# M55M1 register map
File version: 1.0
Registers are 32-bit, read-write, reset 0x0 unless marked. A register's access mark holds for its fields unless they carry their own. Offsets are from the block's base; [hi:lo] are bit positions; 'fields as' and 'values as' point back to an identical list.

## TTMR01 — TTMR Register Map
Base 0x40441000
Same registers: TTMR01_NS 0x50441000
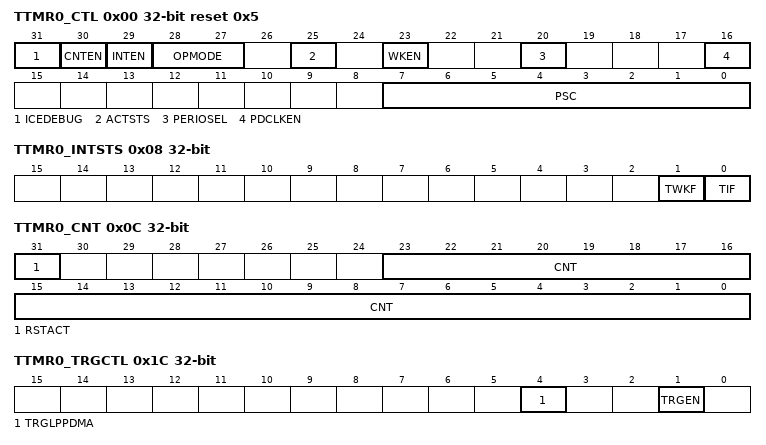
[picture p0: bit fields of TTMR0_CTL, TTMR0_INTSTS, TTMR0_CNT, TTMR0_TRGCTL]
0x00 TTMR0_CTL reset 0x5 — TTMR0 Control Register
  [31] ICEDEBUG — ICE Debug Mode Acknowledge Disable Bit (Write Protect). TIMER counter will keep going no matter CPU is held by ICE or not. Note: This bit is write protected. Refer to the SYS_REGLCTL register.
    0=ICE debug mode acknowledgement effects TIMER counting; 1=ICE debug mode acknowledgement Disabled
  [30] CNTEN — Tick Timer Counting Enable Bit. Note 3: Set enable/disable this bit needs 2 * TTMR_CLK period to become active, user can read ACTSTS (TTMRx_CTL[25]) to check enable/disable command is completed or not.
    0=Stops/Suspends counting; 1=Starts counting
  [29] INTEN — Tick Timer Interrupt Enable Bit. Note: If this bit is enabled, when the tick timer time-out interrupt flag TIF is set to 1, the tick timer interrupt signal is generated and inform to CPU.
    0=Tick Timer time-out interrupt Disabled; 1=Tick Timer time-out interrupt Enabled
  [28:27] OPMODE — Tick Timer Counting Mode Select
    0=The tick controller is operated in One-shot mode; 1=The tick controller is operated in Periodic mode; 3=The tick controller is operated in Continuous Counting mode
  [25] ACTSTS ro — Tick Timer Active Status Bit (Read Only). This bit indicates the 24-bit up counter status. Note: This bit may active when CNT 0 transition to CNT 1.
    0=24-bit up counter is not active; 1=24-bit up counter is active
  [23] WKEN — Wake-up Function Enable Bit. If this bit is set to 1, while timer interrupt flag TIF (TTMRx_INTSTS[0]) is 1 and INTEN (TTMRx_CTL[29]) is enabled, the tick timer interrupt signal will generate a wake-up trigger event to CPU.
    0=Wake-up function Disabled if timer interrupt signal generated; 1=Wake-up function Enabled if timer interrupt signal generated
  [20] PERIOSEL — Periodic Mode Behavior Selection Enable Bit. If updated CMPDAT value CNT, CNT will be reset to default value.
    0=The behavior selection in periodic mode is Disabled; 1=The behavior selection in periodic mode is Enabled
  [16] PDCLKEN — Power-down Engine Clock Enable
    0=Disable engine clock in power-down mode; 1=Enable engine clock in power-down mode
  [7:0] PSC — Prescale Counter. Note: Update prescale counter value will reset internal 8-bit prescale counter and 24-bit up counter value.
0x04 TTMR0_CMP — TTMR0 Comparator Register
  [23:0] CMPDAT — Tick Timer Comparator Value. CMPDAT is a 24-bit compared value register. When the internal 24-bit up counter value is equal to CMPDAT value, the TIF (TTMRx_INTSTS[0] Tick Timer Interrupt Flag) will set to 1. Note 1: Never write 0x0 or 0x1 in CMPDAT field, or the core will run into unknown state. Note 2: When timer is operating at continuous counting mode, the 24-bit up counter will keep counting continuously even if user writes a new value into CMPDAT field. But if timer is operating at other modes, the 24-bit up counter will restart counting from 0 and using newest CMPDAT value to be the tick timer compared value while user writes a new value into CMPDAT field.
0x08 TTMR0_INTSTS — TTMR0 Interrupt Status Register
  [1] TWKF — Tick Timer Wake-up Flag. This bit indicates the interrupt wake-up flag status of timer. Note: This bit is cleared by writing 1 to it.
    0=Tick Timer does not cause CPU wake-up; 1=CPU wake-up from Idle or Power-down mode if timer time-out interrupt signal generated
  [0] TIF — Tick Timer Interrupt Flag. This bit indicates the interrupt flag status of Tick Timer while 24-bit timer up counter CNT (TTMRx_CNT[23:0]) value reaches to CMPDAT (TTMRx_CMP[23:0]) value. Note: This bit is cleared by writing 1 to it.
    0=No effect; 1=CNT value matches the CMPDAT value
0x0C TTMR0_CNT — TTMR0 Data Register
  [31] RSTACT ro — Tick Timer Data Register Reset Active (Read Only). This bit indicates if the counter reset operation active. When user writes this CNT register, tick timer starts to reset its internal 24-bit timer up-counter to 0 and reload 8-bit pre-scale counter. At the same time, timer set this flag to 1 to indicate the counter reset operation is in progress. Once the counter reset operation done, tick timer clear this bit to 0 automatically.
    0=Reset operation is done; 1=Reset operation triggered by writing TTMRx_CNT is in progress
  [23:0] CNT — Tick Timer Data Register. Read operation. Read this register to get CNT value. For example: Write operation. Writing any value to this register will reset current CNT value to 0 and reload internal 8-bit prescale counter.
0x1C TTMR0_TRGCTL — TTMR0 Trigger Control Register
  [4] TRGLPPDMA — Trigger LPPDMA Enable Bit. If this bit is set to 1, each timer time-out event or capture event can be triggered LPPDMA transfer.
    0=Tick Timer interrupt trigger LPPDMA Disabled; 1=Tick Timer interrupt trigger LPPDMA Enabled
  [1] TRGEN — Trigger Low power IPs Enable Bit. If this bit is set to 1, each timer time-out event or capture event can be triggered Low Power IPs conversion.
    0=Tick Timer interrupt trigger Low Power IPs Disabled; 1=Tick Timer interrupt trigger Low Power IPs Enabled
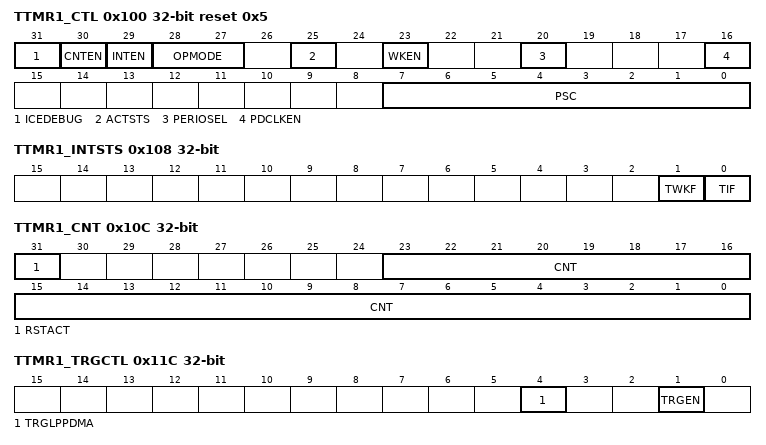
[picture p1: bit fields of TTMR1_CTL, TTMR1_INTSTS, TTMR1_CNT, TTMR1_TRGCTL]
0x100 TTMR1_CTL reset 0x5 — TTMR1 Control Register
  fields as TTMR0_CTL
0x104 TTMR1_CMP — TTMR1 Comparator Register
  fields as TTMR0_CMP
0x108 TTMR1_INTSTS — TTMR1 Interrupt Status Register
  fields as TTMR0_INTSTS
0x10C TTMR1_CNT — TTMR1 Data Register
  fields as TTMR0_CNT
0x11C TTMR1_TRGCTL — TTMR1 Trigger Control Register
  fields as TTMR0_TRGCTL
